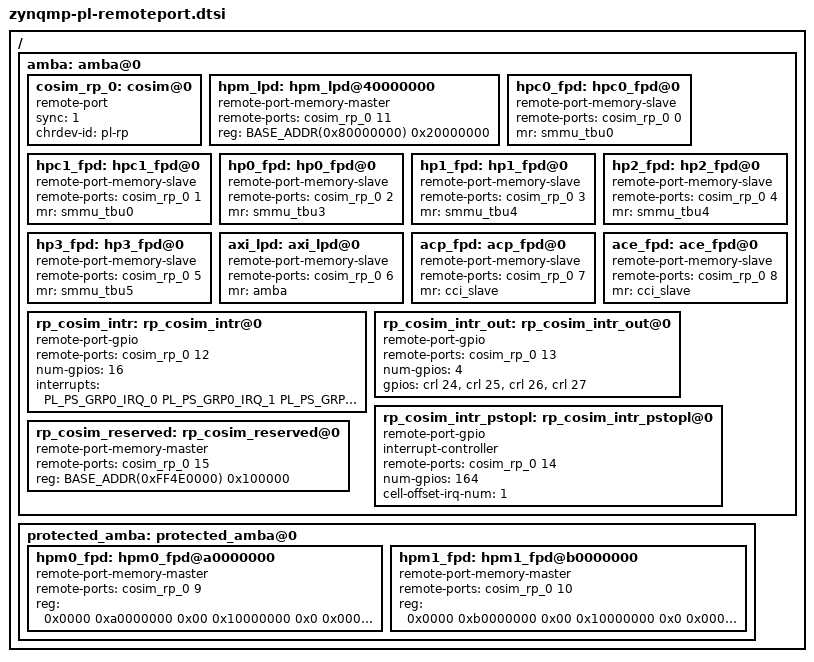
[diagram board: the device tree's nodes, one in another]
/*
 * ZynqMP PL Interface over Remote-port.
 *
 * Copyright (c) 2016, Xilinx Inc
 * All rights reserved.
 *
 * Redistribution and use in source and binary forms, with or without
 * modification, are permitted provided that the following conditions are met:
 *     * Redistributions of source code must retain the above copyright
 *       notice, this list of conditions and the following disclaimer.
 *     * Redistributions in binary form must reproduce the above copyright
 *       notice, this list of conditions and the following disclaimer in the
 *       documentation and/or other materials provided with the distribution.
 *     * Neither the name of the <organization> nor the
 *       names of its contributors may be used to endorse or promote products
 *       derived from this software without specific prior written permission.
 *
 * THIS SOFTWARE IS PROVIDED BY THE COPYRIGHT HOLDERS AND CONTRIBUTORS "AS IS" AND
 * ANY EXPRESS OR IMPLIED WARRANTIES, INCLUDING, BUT NOT LIMITED TO, THE IMPLIED
 * WARRANTIES OF MERCHANTABILITY AND FITNESS FOR A PARTICULAR PURPOSE ARE
 * DISCLAIMED. IN NO EVENT SHALL <COPYRIGHT HOLDER> BE LIABLE FOR ANY
 * DIRECT, INDIRECT, INCIDENTAL, SPECIAL, EXEMPLARY, OR CONSEQUENTIAL DAMAGES
 * (INCLUDING, BUT NOT LIMITED TO, PROCUREMENT OF SUBSTITUTE GOODS OR SERVICES;
 * LOSS OF USE, DATA, OR PROFITS; OR BUSINESS INTERRUPTION) HOWEVER CAUSED AND
 * ON ANY THEORY OF LIABILITY, WHETHER IN CONTRACT, STRICT LIABILITY, OR TORT
 * (INCLUDING NEGLIGENCE OR OTHERWISE) ARISING IN ANY WAY OUT OF THE USE OF THIS
 * SOFTWARE, EVEN IF ADVISED OF THE POSSIBILITY OF SUCH DAMAGE.
 */

/ {
	#address-cells = <MEMORY_ADDRESS_CELLS>;
	#size-cells = <1>;

        amba: amba@0 {
		cosim_rp_0: cosim@0 {
			compatible = "remote-port";
			sync = <1>;
			chrdev-id = "pl-rp";
		};

		/* FIXME: This should only be accessible by the RPU.  */
		hpm_lpd: hpm_lpd@40000000 {
			compatible = "remote-port-memory-master";
			remote-ports = <&cosim_rp_0 11>;
			reg = <BASE_ADDR(0x80000000) 0x20000000>;
		};

		hpc0_fpd: hpc0_fpd@0 {
			compatible = "remote-port-memory-slave";
			remote-ports = <&cosim_rp_0 0>;
			mr = <&smmu_tbu0>;
		};
		hpc1_fpd: hpc1_fpd@0 {
			compatible = "remote-port-memory-slave";
			remote-ports = <&cosim_rp_0 1>;
			mr = <&smmu_tbu0>;
		};
		hp0_fpd: hp0_fpd@0 {
			compatible = "remote-port-memory-slave";
			remote-ports = <&cosim_rp_0 2>;
			mr = <&smmu_tbu3>;
		};
		hp1_fpd: hp1_fpd@0 {
			compatible = "remote-port-memory-slave";
			remote-ports = <&cosim_rp_0 3>;
			mr = <&smmu_tbu4>;
		};
		hp2_fpd: hp2_fpd@0 {
			compatible = "remote-port-memory-slave";
			remote-ports = <&cosim_rp_0 4>;
			mr = <&smmu_tbu4>;
		};
		hp3_fpd: hp3_fpd@0 {
			compatible = "remote-port-memory-slave";
			remote-ports = <&cosim_rp_0 5>;
			mr = <&smmu_tbu5>;
		};
		axi_lpd: axi_lpd@0 {
			compatible = "remote-port-memory-slave";
			remote-ports = <&cosim_rp_0 6>;
			mr = <&amba>;
		};
		acp_fpd: acp_fpd@0 {
			compatible = "remote-port-memory-slave";
			remote-ports = <&cosim_rp_0 7>;
			mr = <&cci_slave>;
		};
		ace_fpd: ace_fpd@0 {
			compatible = "remote-port-memory-slave";
			remote-ports = <&cosim_rp_0 8>;
			mr = <&cci_slave>;
		};

		rp_cosim_intr: rp_cosim_intr@0 {
			compatible = "remote-port-gpio";
			remote-ports = <&cosim_rp_0 12>;
			num-gpios = <16>;
			interrupts = <PL_PS_GRP0_IRQ_0
				       PL_PS_GRP0_IRQ_1
				       PL_PS_GRP0_IRQ_2
				       PL_PS_GRP0_IRQ_3
				       PL_PS_GRP0_IRQ_4
				       PL_PS_GRP0_IRQ_5
				       PL_PS_GRP0_IRQ_6
				       PL_PS_GRP0_IRQ_7
				       PL_PS_GRP1_IRQ_0
				       PL_PS_GRP1_IRQ_1
				       PL_PS_GRP1_IRQ_2
				       PL_PS_GRP1_IRQ_3
				       PL_PS_GRP1_IRQ_4
				       PL_PS_GRP1_IRQ_5
				       PL_PS_GRP1_IRQ_6
				       PL_PS_GRP1_IRQ_7
				    >;
		};
		rp_cosim_intr_out: rp_cosim_intr_out@0 {
			compatible = "remote-port-gpio";
			remote-ports = <&cosim_rp_0 13>;
			num-gpios = <4>;
			gpios = <&crl 24 &crl 25 &crl 26 &crl 27>;
		};
		rp_cosim_intr_pstopl: rp_cosim_intr_pstopl@0 {
			#interrupt-cells = <3>;
			interrupt-controller;
			compatible = "remote-port-gpio";
			remote-ports = <&cosim_rp_0 14>;
			num-gpios = <164>;
			cell-offset-irq-num = <1>;
		};
		/* This area can be used for implentation specific emulation*/
		rp_cosim_reserved: rp_cosim_reserved@0{
			compatible = "remote-port-memory-master";
			remote-ports = <&cosim_rp_0 15>;
			reg = <BASE_ADDR(0xFF4E0000) 0x100000>;
		};
	};

	protected_amba: protected_amba@0 {
		/*
		 * HPM0 has 3 appertures that all map onto the same AXI port.
		 * 0x0000.a0000000 - 0x0000.b0000000   (256MB)
		 * 0x0004.00000000 - 0x0005.00000000   (4GB)
		 * 0x0010.00000000 - 0x0048.00000000   (224GB)
		 */
		hpm0_fpd: hpm0_fpd@a0000000 {
			compatible = "remote-port-memory-master";
			remote-ports = <&cosim_rp_0 9>;
			reg = <0x0000 0xa0000000 0x00 0x10000000 0x0
			       0x0004 0x00000000 0x01 0x00000000 0x0
			       0x0010 0x00000000 0x38 0x00000000 0x0 >;
		};

		/*
		 * HPM1 has 3 appertures that all map onto the same AXI port.
		 * 0x0000.b0000000 - 0x0000.c0000000   (256MB)
		 * 0x0005.00000000 - 0x0006.00000000   (4GB)
		 * 0x0048.00000000 - 0x0080.00000000   (224GB)
		 */
		hpm1_fpd: hpm1_fpd@b0000000 {
			compatible = "remote-port-memory-master";
			remote-ports = <&cosim_rp_0 10>;
			reg = <0x0000 0xb0000000 0x00 0x10000000 0x0
			       0x0005 0x00000000 0x01 0x00000000 0x0
			       0x0048 0x00000000 0x38 0x00000000 0x0 >;
		};
	};
};
